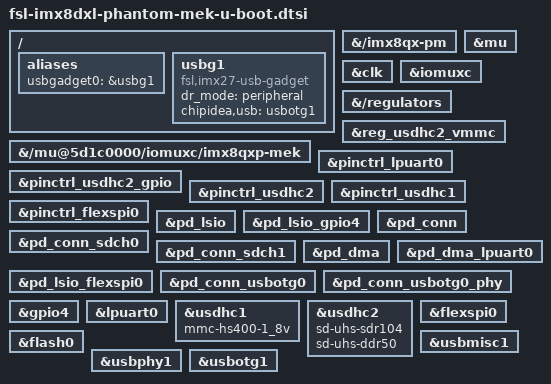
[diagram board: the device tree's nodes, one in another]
// SPDX-License-Identifier: GPL-2.0+
/*
 * Copyright 2019 NXP
 */

/ {
	aliases {
		usbgadget0 = &usbg1;
	};

	usbg1: usbg1 {
		compatible = "fsl,imx27-usb-gadget";
		dr_mode = "peripheral";
		chipidea,usb = <&usbotg1>;
		status = "okay";
		u-boot,dm-spl;
	};
};

&{/imx8qx-pm} {

	u-boot,dm-spl;
};

&mu {
	u-boot,dm-spl;
};

&clk {
	u-boot,dm-spl;
};

&iomuxc {
	u-boot,dm-spl;
};

&{/regulators} {
	u-boot,dm-spl;
};

&reg_usdhc2_vmmc {
	u-boot,dm-spl;
};

&{/mu@5d1c0000/iomuxc/imx8qxp-mek} {
	u-boot,dm-spl;
};

&pinctrl_lpuart0 {
	u-boot,dm-spl;
};

&pinctrl_usdhc2_gpio {
	u-boot,dm-spl;
};

&pinctrl_usdhc2 {
	u-boot,dm-spl;
};

&pinctrl_usdhc1 {
	u-boot,dm-spl;
};

&pinctrl_flexspi0 {
	u-boot,dm-spl;
};

&pd_lsio {
	u-boot,dm-spl;
};

&pd_lsio_gpio4 {
	u-boot,dm-spl;
};

&pd_conn {
	u-boot,dm-spl;
};

&pd_conn_sdch0 {
	u-boot,dm-spl;
};

&pd_conn_sdch1 {
	u-boot,dm-spl;
};

&pd_dma {
	u-boot,dm-spl;
};

&pd_dma_lpuart0 {
	u-boot,dm-spl;
};

&pd_lsio_flexspi0 {
	u-boot,dm-spl;
};

&pd_conn_usbotg0 {
	u-boot,dm-spl;
};

&pd_conn_usbotg0_phy {
	u-boot,dm-spl;
};

&gpio4 {
	u-boot,dm-spl;
};

&lpuart0 {
	u-boot,dm-spl;
};

&usdhc1 {
	u-boot,dm-spl;
	mmc-hs400-1_8v;
};

&usdhc2 {
	u-boot,dm-spl;
	sd-uhs-sdr104;
	sd-uhs-ddr50;
};

&flexspi0 {
	u-boot,dm-spl;
};

&flash0 {
	u-boot,dm-spl;
};

&usbmisc1 {
	u-boot,dm-spl;
};

&usbphy1 {
	u-boot,dm-spl;
};

&usbotg1 {
	u-boot,dm-spl;
};
